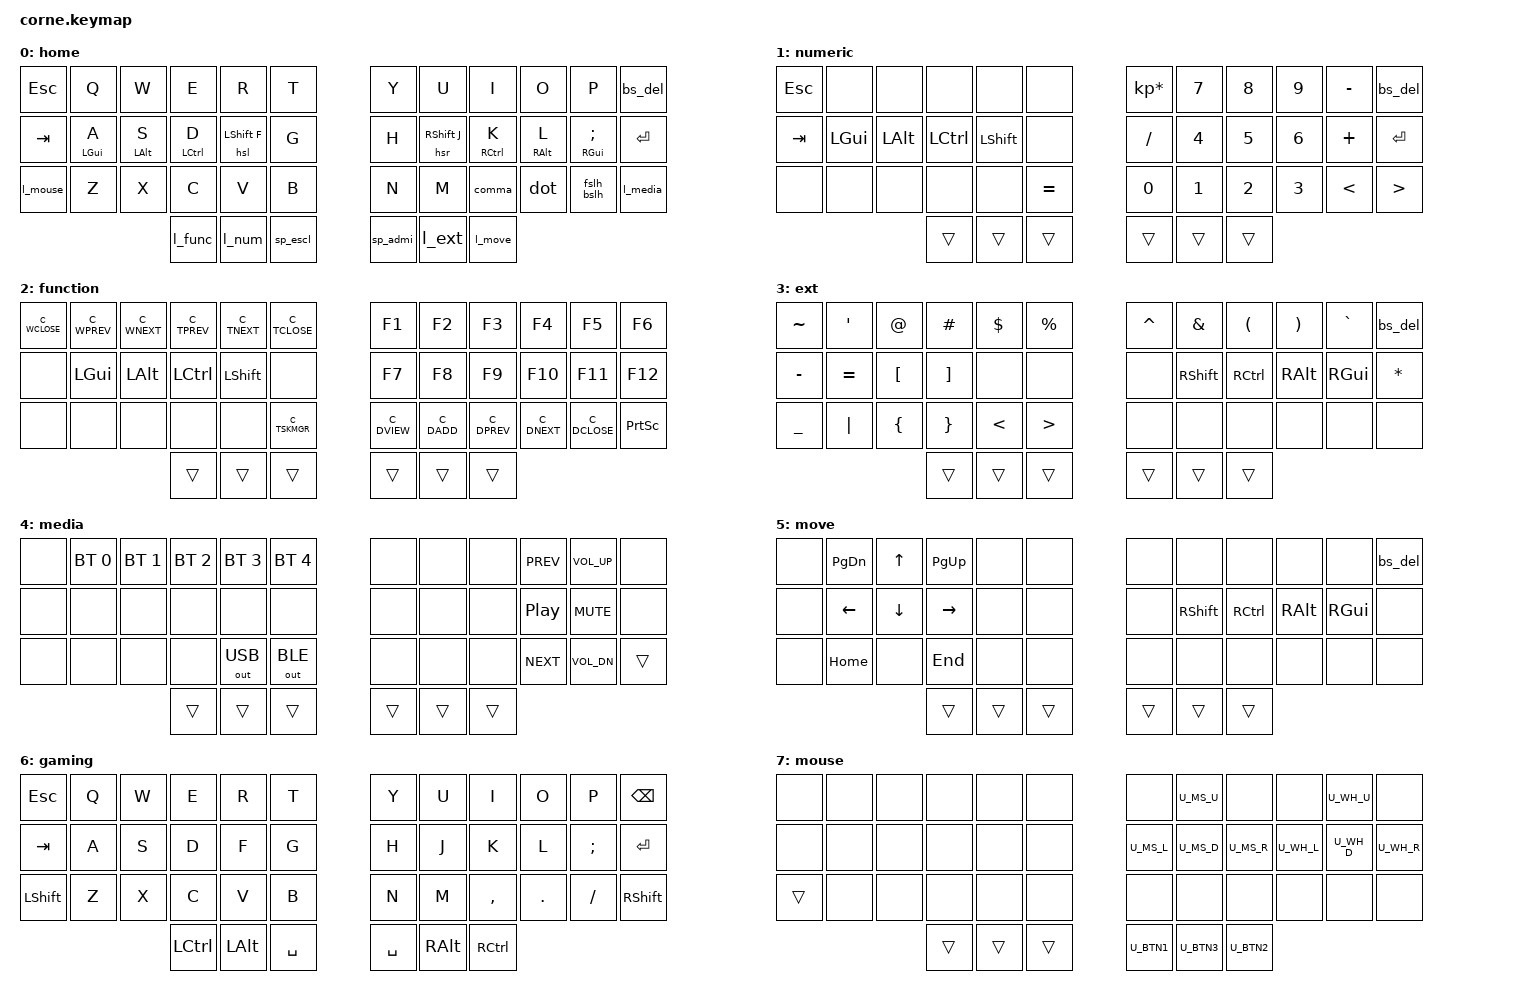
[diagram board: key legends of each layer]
/*
=== === === === === === === === === === === ===
    INCLUDES
=== === === === === === === === === === === ===
*/

#include <behaviors.dtsi>
#include <dt-bindings/zmk/keys.h>
#include <dt-bindings/zmk/bt.h>
#include <dt-bindings/zmk/outputs.h>
#include "../config/includes/parameters.h"
#include "../config/includes/helper.h"
#include "../config/includes/keypos_42keys.h"
#include "../config/includes/mouse.dtsi"

//=========================
//  BEHAVIORS DEFINITION
//=========================
ZMK_BEHAVIOR(swapper,         tri_state,    bindings = <&kt LALT>, <&kp TAB>, <&kt LALT>; ignored-key-positions = <LT4>; )
ZMK_BEHAVIOR(copy_cut,        tap_dance,    tapping-term-ms = <200>; bindings = <C_COPY>, <C_CUT>; )
ZMK_BEHAVIOR(hml,             hold_tap,     #binding-cells = <2>; bindings = <&kp>,  <&kp>; flavor = "balanced"; quick-tap-ms = <175>; require-prior-idle-ms = <150>; tapping-term-ms = <300>; quick-tap-ms = <175>; hold-trigger-key-positions = <KEYS_R KEYS_T>; hold-trigger-on-release; )
ZMK_BEHAVIOR(hmr,             hold_tap,     #binding-cells = <2>; bindings = <&kp>,  <&kp>; flavor = "balanced"; quick-tap-ms = <175>; require-prior-idle-ms = <150>; tapping-term-ms = <300>; quick-tap-ms = <175>; hold-trigger-key-positions = <KEYS_L KEYS_T>; hold-trigger-on-release; )
ZMK_BEHAVIOR(hsl,             hold_tap,     #binding-cells = <2>; bindings = <&kp>,  <&kp>; flavor = "balanced"; quick-tap-ms = <175>; tapping-term-ms = <200>; quick-tap-ms = <175>; hold-trigger-key-positions = <KEYS_R KEYS_T>; )
ZMK_BEHAVIOR(hsr,             hold_tap,     #binding-cells = <2>; bindings = <&kp>,  <&kp>; flavor = "balanced"; quick-tap-ms = <175>; tapping-term-ms = <200>; quick-tap-ms = <175>; hold-trigger-key-positions = <KEYS_L KEYS_T>; )
ZMK_BEHAVIOR(bs_del,          mod_morph,    bindings = <&kp BSPC>, <&kp DEL>; mods = <(MOD_LSFT|MOD_RSFT)>; keep-mods = <(MOD_RSFT|MOD_LCTL|MOD_RCTL)>; )
ZMK_BEHAVIOR(sp_escl,         mod_morph,    bindings = <&kp SPACE>, <&kp EXCL>; mods = <(MOD_LSFT|MOD_RSFT)>;)
ZMK_BEHAVIOR(sp_admi,         mod_morph,    bindings = <&kp SPACE>, <&kp QMARK>; mods = <(MOD_LSFT|MOD_RSFT)>;)
ZMK_BEHAVIOR(fslh_bslh,       mod_morph,    bindings = <&kp FSLH>, <&kp BSLH>; mods = <(MOD_LSFT|MOD_RSFT)>;)
ZMK_BEHAVIOR(dot,             mod_morph,    bindings = <&kp DOT>, <&kp COLON>; mods = <(MOD_LSFT|MOD_RSFT)>;)
ZMK_BEHAVIOR(comma,           mod_morph,    bindings = <&kp COMMA>, <&kp SEMI>; mods = <(MOD_LSFT|MOD_RSFT)>;)
ZMK_BEHAVIOR(l_func,          tap_dance,    tapping-term-ms = <200>; bindings = <&mo L_FUNC>, <&tog L_FUNC>; )
ZMK_BEHAVIOR(l_num,           tap_dance,    tapping-term-ms = <200>; bindings = <&mo L_NUM>, <&tog L_NUM>; )
ZMK_BEHAVIOR(l_ext,           tap_dance,    tapping-term-ms = <200>; bindings = <&mo L_EXT>, <&tog L_EXT>; )
ZMK_BEHAVIOR(l_move,          tap_dance,    tapping-term-ms = <200>; bindings = <&mo L_MOVE>, <&tog L_MOVE>; )
ZMK_BEHAVIOR(l_mouse,         tap_dance,    tapping-term-ms = <200>; bindings = <&mo L_MOUSE>, <&tog L_MOUSE>; )
ZMK_BEHAVIOR(l_media,         tap_dance,    tapping-term-ms = <200>; bindings = <&mo L_MEDIA>, <&tog L_MEDIA>; )

//=========================
//  COMBO DEFINITION
//=========================
ZMK_COMBO(delete,       &kp DELETE,         RT4 RT5,        L_HOME L_EXT L_MOVE,    COMBO_TERM_FAST)
ZMK_COMBO(caps,         &kp CAPSLOCK,       LM1 RM1,        L_HOME,                 COMBO_TERM_SLOW)
ZMK_COMBO(caps2,        &kp CAPSLOCK,       RM0 RM1,        L_HOME,                 COMBO_TERM_SLOW)
ZMK_COMBO(btclr,        &bt BT_CLR,         LH2 LH1,        L_MEDIA,                COMBO_TERM_SLOW)
// Shortcuts
ZMK_COMBO(find,         C_FIND,             LM1 LM0,        L_HOME,                 COMBO_TERM_FAST)
ZMK_COMBO(select_all,   C_SELECT_ALL,       LB5 LB4,        L_HOME,                 COMBO_TERM_FAST)
ZMK_COMBO(copy_cut,     &copy_cut,          LB2 LB1,        L_HOME,                 COMBO_TERM_SLOW)
ZMK_COMBO(paste,        C_PASTE,            LB1 LB0,        L_HOME,                 COMBO_TERM_SLOW)
ZMK_COMBO(undo,         C_UNDO,             LT5 LT4,        L_HOME,                 COMBO_TERM_FAST)
ZMK_COMBO(redo,         C_REDO,             LT5 LT4 LT3,    L_HOME,                 COMBO_TERM_FAST)
ZMK_COMBO(ctrlenter,    C_CTRLENT,          RM4 RM5,        L_HOME,                 COMBO_TERM_FAST)
ZMK_COMBO(command,      C_COMMAND,          RB0 RB1,        L_HOME,                 COMBO_TERM_FAST)
ZMK_COMBO(files,        C_FILES,            RB1 RB2,        L_HOME,                 COMBO_TERM_FAST)
ZMK_COMBO(format,       C_FORMAT,           RB3 RB4,        L_HOME,                 COMBO_TERM_FAST)
ZMK_COMBO(save,         C_SAVE,             RB4 RB5,        L_HOME,                 COMBO_TERM_FAST)
// Gaming Layer
ZMK_COMBO(egaming,      &tog L_GAMING,      LH2 LH1,        L_HOME L_GAMING,        COMBO_TERM_SLOW)
ZMK_COMBO(caps,         &kp CAPSLOCK,       LB5 LB4,        L_GAMING,               COMBO_TERM_FAST)
ZMK_COMBO(gan1,         &kp N1,             LT5 LT4,        L_GAMING,               COMBO_TERM_FAST)
ZMK_COMBO(gan2,         &kp N2,             LT4 LT3,        L_GAMING,               COMBO_TERM_FAST)
ZMK_COMBO(gan3,         &kp N3,             LT3 LT2,        L_GAMING,               COMBO_TERM_FAST)
ZMK_COMBO(gan4,         &kp N4,             LT2 LT1,        L_GAMING,               COMBO_TERM_FAST)
ZMK_COMBO(gan5,         &kp N5,             LT1 LT0,        L_GAMING,               COMBO_TERM_FAST)
ZMK_COMBO(kf1,          &kp F1,             RT0 RM0,        L_GAMING,               COMBO_TERM_FAST)
ZMK_COMBO(kf2,          &kp F2,             RT1 RM1,        L_GAMING,               COMBO_TERM_FAST)
ZMK_COMBO(kf3,          &kp F3,             RT2 RM2,        L_GAMING,               COMBO_TERM_FAST)
ZMK_COMBO(kf4,          &kp F4,             RT3 RM3,        L_GAMING,               COMBO_TERM_FAST)
ZMK_COMBO(kf5,          &kp F5,             RT4 RM4,        L_GAMING,               COMBO_TERM_FAST)
ZMK_COMBO(kf6,          &kp F6,             RT5 RM5,        L_GAMING,               COMBO_TERM_FAST)
ZMK_COMBO(kf7,          &kp F7,             RM0 RB0,        L_GAMING,               COMBO_TERM_FAST)
ZMK_COMBO(kf8,          &kp F8,             RM1 RB1,        L_GAMING,               COMBO_TERM_FAST)
ZMK_COMBO(kf9,          &kp F9,             RM2 RB2,        L_GAMING,               COMBO_TERM_FAST)
ZMK_COMBO(kf10,         &kp F10,            RM3 RB3,        L_GAMING,               COMBO_TERM_FAST)
ZMK_COMBO(kf11,         &kp F11,            RM4 RB4,        L_GAMING,               COMBO_TERM_FAST)
ZMK_COMBO(kf12,         &kp F12,            RM5 RB5,        L_GAMING,               COMBO_TERM_FAST)


//=========================
//  LAYERS DEFINITION
//=========================
ZMK_LAYER(home,
                &kp ESC       &kp Q         &kp W         &kp E         &kp R         &kp T             &kp Y         &kp U         &kp I         &kp O         &kp P          &bs_del
                &kp TAB       &hml LGUI A   &hml LALT S   &hml LCTRL D  &hsl LSHFT F  &kp G             &kp H         &hsr RSHFT J  &hmr RCTRL K  &hmr RALT L   &hmr RGUI SEMI &kp ENTER
                &l_mouse      &kp Z         &kp X         &kp C         &kp V         &kp B             &kp N         &kp M         &comma        &dot          &fslh_bslh     &l_media
                                                          &l_func       &l_num        &sp_escl          &sp_admi      &l_ext        &l_move
) //===================================================================================================================================================================================
ZMK_LAYER(numeric,
                &kp ESC       &none         &none         &none         &none         &none             &kp KP_MULTIPLY &kp N7      &kp N8        &kp N9        &kp MINUS      &bs_del
                &kp TAB       &kp LGUI      &kp LALT      &kp LCTRL     &kp LSHFT     &none             &kp FSLH        &kp N4      &kp N5        &kp N6        &kp PLUS       &kp ENTER
                &none         &none         &none         &none         &none         &kp EQUAL         &kp N0          &kp N1      &kp N2        &kp N3        &kp LT         &kp GT
                                                          &trans        &trans        &trans            &trans          &trans      &trans
) //===================================================================================================================================================================================
ZMK_LAYER(function,
                C_WCLOSE      C_WPREV       C_WNEXT       C_TPREV       C_TNEXT       C_TCLOSE          &kp F1        &kp F2        &kp F3        &kp F4        &kp F5         &kp F6
                &none         &kp LGUI      &kp LALT      &kp LCTRL     &kp LSHFT     &none             &kp F7        &kp F8        &kp F9        &kp F10       &kp F11        &kp F12
                &none         &none         &none         &none         &none         C_TSKMGR          C_DVIEW       C_DADD        C_DPREV       C_DNEXT       C_DCLOSE       &kp PSCRN
                                                          &trans        &trans        &trans            &trans        &trans        &trans
) //===================================================================================================================================================================================
ZMK_LAYER(ext,
                &kp TILDE     &kp SQT       &kp AT        &kp HASH      &kp DLLR      &kp PRCNT         &kp CARET     &kp AMPS      &kp LPAR      &kp RPAR      &kp GRAVE      &bs_del
                &kp MINUS     &kp EQUAL     &kp LBKT      &kp RBKT      &none         &none             &none         &kp RSHFT     &kp RCTRL     &kp RALT      &kp RGUI       &kp ASTRK
                &kp UNDER     &kp PIPE      &kp LBRC      &kp RBRC      &kp LT        &kp GT            &none         &none         &none         &none         &none          &none
                                                          &trans        &trans        &trans            &trans        &trans        &trans
) //===================================================================================================================================================================================
ZMK_LAYER(media,
                &none         &bt BT_SEL 0  &bt BT_SEL 1  &bt BT_SEL 2  &bt BT_SEL 3  &bt BT_SEL 4      &none         &none         &none         &kp C_PREV    &kp C_VOL_UP   &none
                &none         &none         &none         &none         &none         &none             &none         &none         &none         &kp C_PP      &kp C_MUTE     &none
                &none         &none         &none         &none         &out OUT_USB  &out OUT_BLE      &none         &none         &none         &kp C_NEXT    &kp C_VOL_DN   &trans
                                                          &trans        &trans        &trans            &trans        &trans        &trans
) //===================================================================================================================================================================================
ZMK_LAYER(move,
                &none         &kp PAGE_DOWN  &kp UP       &kp PAGE_UP   &none         &none             &none         &none         &none         &none         &none          &bs_del
                &none         &kp LEFT       &kp DOWN     &kp RIGHT     &none         &none             &none         &kp RSHFT     &kp RCTRL     &kp RALT      &kp RGUI       &none
                &none         &kp HOME       &none        &kp END       &none         &none             &none         &none         &none         &none         &none          &none
                                                          &trans        &trans        &trans            &trans        &trans        &trans
) //===================================================================================================================================================================================
ZMK_LAYER(gaming,
                &kp ESC       &kp Q         &kp W         &kp E         &kp R         &kp T             &kp Y         &kp U         &kp I         &kp O         &kp P          &kp BSPC
                &kp TAB       &kp A         &kp S         &kp D         &kp F         &kp G             &kp H         &kp J         &kp K         &kp L         &kp SEMI       &kp ENTER
                &kp LSHFT     &kp Z         &kp X         &kp C         &kp V         &kp B             &kp N         &kp M         &kp COMMA     &kp DOT       &kp FSLH       &kp RSHIFT
                                                          &kp LCTRL     &kp LALT      &kp SPACE         &kp SPACE     &kp RALT      &kp RCTRL
) //===================================================================================================================================================================================
ZMK_LAYER(mouse,
                &none         &none         &none         &none         &none         &none             &none         U_MS_U        &none         &none         U_WH_U         &none
                &none         &none         &none         &none         &none         &none             U_MS_L        U_MS_D        U_MS_R        U_WH_L        U_WH_D         U_WH_R
                &trans        &none         &none         &none         &none         &none             &none         &none         &none         &none         &none          &none
                                                          &trans        &trans        &trans            U_BTN1        U_BTN3        U_BTN2
) //===================================================================================================================================================================================
